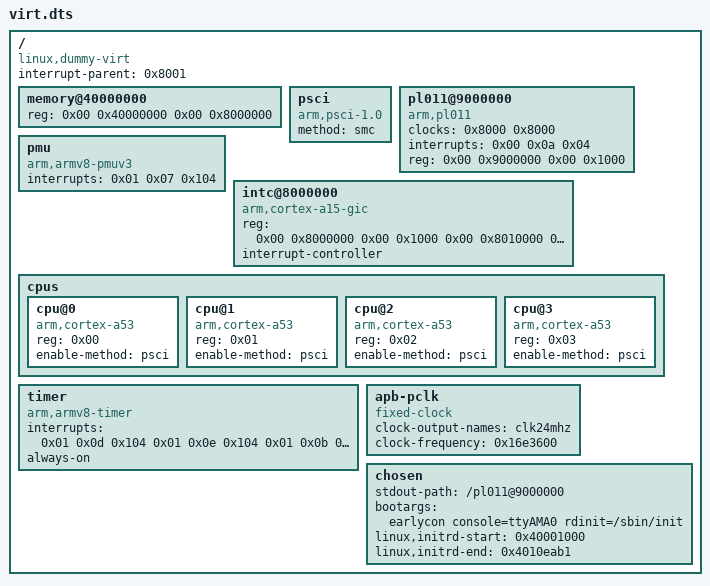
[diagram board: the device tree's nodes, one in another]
/dts-v1/;

/ {
	interrupt-parent = <0x8001>;
	#size-cells = <0x02>;
	#address-cells = <0x02>;
	compatible = "linux,dummy-virt";

	memory@40000000 {
		reg = <0x00 0x40000000 0x00 0x8000000>;
		device_type = "memory";
	};

	psci {
		compatible = "arm,psci-1.0";
		method = "smc";
		status = "okay";
	};

	pl011@9000000 {
		clock-names = "uartclk\0apb_pclk";
		clocks = <0x8000 0x8000>;
		interrupts = <0x00 0x0a 0x04>;
		reg = <0x00 0x9000000 0x00 0x1000>;
		compatible = "arm,pl011\0arm,primecell";
	};

	pmu {
		interrupts = <0x01 0x07 0x104>;
		compatible = "arm,armv8-pmuv3";
	};

	intc@8000000 {
		phandle = <0x8001>;
		reg = <0x00 0x8000000 0x00 0x1000 0x00 0x8010000 0x00 0x2000>;
		compatible = "arm,cortex-a15-gic";
		ranges;
		#size-cells = <0x02>;
		#address-cells = <0x02>;
		interrupt-controller;
		#interrupt-cells = <0x03>;
		status = "okay";
	};


	cpus {
		#size-cells = <0x00>;
		#address-cells = <0x01>;

		cpu@0 {
			reg = <0x00>;
			compatible = "arm,cortex-a53";
			device_type = "cpu";
			enable-method = "psci";
		};
		cpu@1 {
			reg = <0x01>;
			compatible = "arm,cortex-a53";
			device_type = "cpu";
			enable-method = "psci";
		};
		cpu@2 {
			reg = <0x02>;
			compatible = "arm,cortex-a53";
			device_type = "cpu";
			enable-method = "psci";
		};
		cpu@3 {
			reg = <0x03>;
			compatible = "arm,cortex-a53";
			device_type = "cpu";
			enable-method = "psci";
		};
	};

	timer {
		interrupts = <0x01 0x0d 0x104 0x01 0x0e 0x104 0x01 0x0b 0x104 0x01 0x0a 0x104>;
		always-on;
		compatible = "arm,armv8-timer\0arm,armv7-timer";
	};

	apb-pclk {
		phandle = <0x8000>;
		clock-output-names = "clk24mhz";
		clock-frequency = <0x16e3600>;
		#clock-cells = <0x00>;
		compatible = "fixed-clock";
	};

	chosen {
		stdout-path = "/pl011@9000000";
		bootargs = "earlycon console=ttyAMA0 rdinit=/sbin/init";
		linux,initrd-start = <0x40001000>;
		linux,initrd-end = <0x4010eab1>;
	};
};
